AUTOSAR XML (schema 314)
package /ComponentType
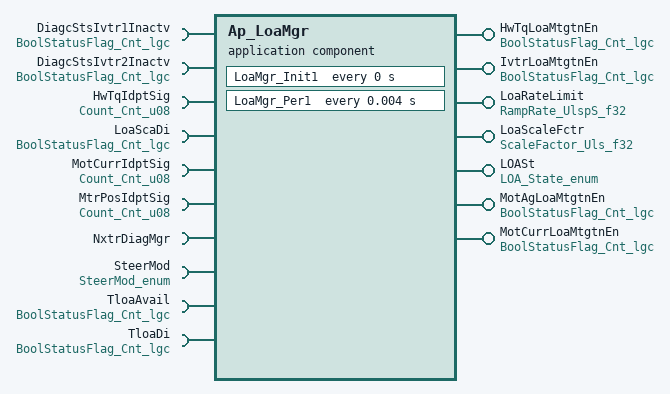
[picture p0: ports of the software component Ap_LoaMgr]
  application software component type Ap_LoaMgr
    7 x provide port:
      HwTqLoaMtgtnEn: unqueued-sender-com-spec{data-element=Cnt_lgc, can-invalidate=false, init-value=D_FALSE_CNT_LGC}, provided-interface=BoolStatusFlag_Cnt_lgc
      IvtrLoaMtgtnEn: unqueued-sender-com-spec{data-element=Cnt_lgc, can-invalidate=false, init-value=D_FALSE_CNT_LGC}, provided-interface=BoolStatusFlag_Cnt_lgc
      LoaRateLimit: unqueued-sender-com-spec{data-element=UlspS_f32, can-invalidate=false, init-value=D_ONE_ULS_F32}, provided-interface=RampRate_UlspS_f32
      LoaScaleFctr: unqueued-sender-com-spec{data-element=Uls_f32, can-invalidate=false, init-value=D_ONE_ULS_F32}, provided-interface=ScaleFactor_Uls_f32
      LOASt: unqueued-sender-com-spec{data-element=State_enum, can-invalidate=false, init-value=D_LOASTATEINIT_CNT_ENUM}, provided-interface=LOA_State_enum
      MotAgLoaMtgtnEn: unqueued-sender-com-spec{data-element=Cnt_lgc, can-invalidate=false, init-value=D_FALSE_CNT_LGC}, provided-interface=BoolStatusFlag_Cnt_lgc
      MotCurrLoaMtgtnEn: unqueued-sender-com-spec{data-element=Cnt_lgc, can-invalidate=false, init-value=D_FALSE_CNT_LGC}, provided-interface=BoolStatusFlag_Cnt_lgc
    10 x require port:
      DiagcStsIvtr1Inactv: unqueued-receiver-com-spec{data-element=Cnt_lgc, init-value=D_FALSE_CNT_LGC}, required-interface=BoolStatusFlag_Cnt_lgc
      DiagcStsIvtr2Inactv: unqueued-receiver-com-spec{data-element=Cnt_lgc, init-value=D_FALSE_CNT_LGC}, required-interface=BoolStatusFlag_Cnt_lgc
      HwTqIdptSig: unqueued-receiver-com-spec{data-element=Cnt_u08, init-value=D_FOUR_CNT_U08}, required-interface=Count_Cnt_u08
      LoaScaDi: unqueued-receiver-com-spec{data-element=Cnt_lgc, init-value=D_FALSE_CNT_LGC}, required-interface=BoolStatusFlag_Cnt_lgc
      MotCurrIdptSig: unqueued-receiver-com-spec{data-element=Cnt_u08, init-value=D_TWO_CNT_U08}, required-interface=Count_Cnt_u08
      MtrPosIdptSig: unqueued-receiver-com-spec{data-element=Cnt_u08, init-value=D_THREE_CNT_U08}, required-interface=Count_Cnt_u08
      NxtrDiagMgr: required-com-specs=[GetNTCActive, GetNTCFailed, GetNTCStatus, SetNTCStatus], required-interface=NxtrDiagMgr
      SteerMod: unqueued-receiver-com-spec{data-element=Cnt_enum, init-value=D_STEERMODINIT_CNT_ENUM}, required-interface=SteerMod_enum
      TloaAvail: unqueued-receiver-com-spec{data-element=Cnt_lgc, init-value=D_FALSE_CNT_LGC}, required-interface=BoolStatusFlag_Cnt_lgc
      TloaDi: unqueued-receiver-com-spec{data-element=Cnt_lgc, init-value=D_FALSE_CNT_LGC}, required-interface=BoolStatusFlag_Cnt_lgc
  internal behavior Ap_LoaMgr_InternalBehavior: component=Ap_LoaMgr
    timing event LoaMgr_Init1_InitEvent: start-on-event=LoaMgr_Init1, period=0
    timing event TMT_LoaMgr_Per1: start-on-event=LoaMgr_Per1, period=0.004
    exclusive area EaLoaScaleAndRate
    port-api-options:
      enable-take-address=false, indirect-api=false, port=DiagcStsIvtr1Inactv
      enable-take-address=false, indirect-api=false, port=DiagcStsIvtr2Inactv
      enable-take-address=false, indirect-api=false, port=HwTqIdptSig
      enable-take-address=false, indirect-api=false, port=HwTqLoaMtgtnEn
      enable-take-address=false, indirect-api=false, port=IvtrLoaMtgtnEn
      enable-take-address=false, indirect-api=false, port=LoaRateLimit
      enable-take-address=false, indirect-api=false, port=LoaScaDi
      enable-take-address=false, indirect-api=false, port=LoaScaleFctr
      enable-take-address=false, indirect-api=false, port=LOASt
      enable-take-address=false, indirect-api=false, port=MotAgLoaMtgtnEn
      enable-take-address=false, indirect-api=false, port=MotCurrIdptSig
      enable-take-address=false, indirect-api=false, port=MotCurrLoaMtgtnEn
      enable-take-address=false, indirect-api=false, port=MtrPosIdptSig
      enable-take-address=false, indirect-api=false, port=NxtrDiagMgr
      enable-take-address=false, indirect-api=false, port=SteerMod
      enable-take-address=false, indirect-api=false, port=TloaAvail
      enable-take-address=false, indirect-api=false, port=TloaDi
    runnable LoaMgr_Init1
      4 x sync call, all with timeout=0:
        SC_NxtrDiagMgr_GetNTCActive: operation=NxtrDiagMgr.GetNTCActive
        SC_NxtrDiagMgr_GetNTCFailed: operation=NxtrDiagMgr.GetNTCFailed
        SC_NxtrDiagMgr_GetNTCStatus: operation=NxtrDiagMgr.GetNTCStatus
        SC_NxtrDiagMgr_SetNTCStatus: operation=NxtrDiagMgr.SetNTCStatus
    runnable LoaMgr_Per1: can-enter-exclusive-area=EaLoaScaleAndRate
      9 x data read access:
        READ_DiagcStsIvtr1Inactv_Cnt_lgc: data-element=DiagcStsIvtr1Inactv.Cnt_lgc
        READ_DiagcStsIvtr2Inactv_Cnt_lgc: data-element=DiagcStsIvtr2Inactv.Cnt_lgc
        READ_HwTqIdptSig_Cnt_u08: data-element=HwTqIdptSig.Cnt_u08
        READ_LoaScaDi_Cnt_lgc: data-element=LoaScaDi.Cnt_lgc
        READ_MotCurrIdptSig_Cnt_u08: data-element=MotCurrIdptSig.Cnt_u08
        READ_MtrPosIdptSig_Cnt_u08: data-element=MtrPosIdptSig.Cnt_u08
        READ_SteerMod_Cnt_enum: data-element=SteerMod.Cnt_enum
        READ_TloaAvail_Cnt_lgc: data-element=TloaAvail.Cnt_lgc
        READ_TloaDi_Cnt_lgc: data-element=TloaDi.Cnt_lgc
      data send point SEND_LoaRateLimit_UlspS_f32: data-element=LoaRateLimit.UlspS_f32
      data send point SEND_LoaScaleFctr_Uls_f32: data-element=LoaScaleFctr.Uls_f32
      5 x data write access:
        WRITE_HwTqLoaMtgtnEn_Cnt_lgc: data-element=HwTqLoaMtgtnEn.Cnt_lgc
        WRITE_IvtrLoaMtgtnEn_Cnt_lgc: data-element=IvtrLoaMtgtnEn.Cnt_lgc
        WRITE_LOASt_State_enum: data-element=LOASt.State_enum
        WRITE_MotAgLoaMtgtnEn_Cnt_lgc: data-element=MotAgLoaMtgtnEn.Cnt_lgc
        WRITE_MotCurrLoaMtgtnEn_Cnt_lgc: data-element=MotCurrLoaMtgtnEn.Cnt_lgc
      4 x sync call, all with timeout=0:
        SC_NxtrDiagMgr_GetNTCActive: operation=NxtrDiagMgr.GetNTCActive
        SC_NxtrDiagMgr_GetNTCFailed: operation=NxtrDiagMgr.GetNTCFailed
        SC_NxtrDiagMgr_GetNTCStatus: operation=NxtrDiagMgr.GetNTCStatus
        SC_NxtrDiagMgr_SetNTCStatus: operation=NxtrDiagMgr.SetNTCStatus
  swc implementation Ap_LoaMgr_Implementation: behavior=Ap_LoaMgr_InternalBehavior
    code-descriptors:
      code Code: type=SRC
